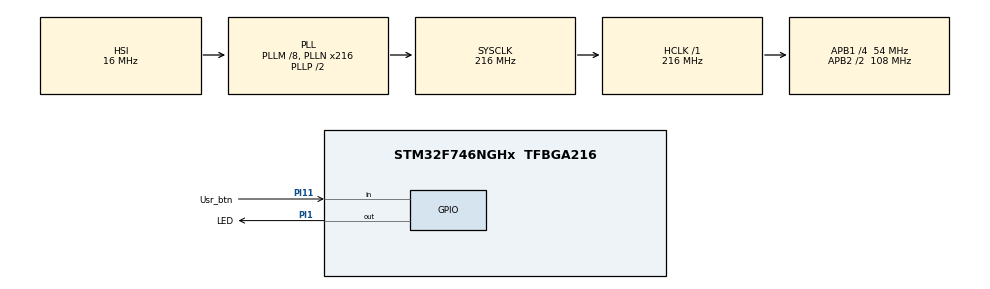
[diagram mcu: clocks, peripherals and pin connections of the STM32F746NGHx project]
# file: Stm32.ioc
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FREERTOS.Tasks01=defaultTask,24,128,StartDefaultTask,Default,NULL,Dynamic,NULL,NULL;ButtonTask,8,128,ButtonTask1,Default,NULL,Dynamic,NULL,NULL
Mcu.Family=STM32F7
Mcu.Name=STM32F746NGHx
Mcu.Package=TFBGA216
NVIC.PriorityGroup=NVIC_PRIORITYGROUP_4
PA13.Mode=Serial_Wire
PA13.Signal=SYS_JTMS-SWDIO
PA14.Mode=Serial_Wire
PA14.Signal=SYS_JTCK-SWCLK
PI1.GPIO_Label=LED
PI1.PinState=GPIO_PIN_SET
PI1.Signal=GPIO_Output
PI11.GPIO_Label=Usr_btn
PI11.Signal=GPIO_Input
ProjectManager.HeapSize=0x200
ProjectManager.StackSize=0x400
ProjectManager.TargetToolchain=STM32CubeIDE
RCC.AHBFreq_Value=216000000
RCC.APB1CLKDivider=RCC_HCLK_DIV4
RCC.APB1Freq_Value=54000000
RCC.APB1TimFreq_Value=108000000
RCC.APB2CLKDivider=RCC_HCLK_DIV2
RCC.APB2Freq_Value=108000000
RCC.APB2TimFreq_Value=216000000
RCC.CortexFreq_Value=216000000
RCC.HCLKFreq_Value=216000000
RCC.HSE_VALUE=25000000
RCC.HSI_VALUE=16000000
RCC.LSE_VALUE=32768
RCC.PLLM=8
RCC.PLLN=216
RCC.SYSCLKFreq_VALUE=216000000
RCC.SYSCLKSource=RCC_SYSCLKSOURCE_PLLCLK
RCC.USBFreq_Value=216000000
RCC.VCOOutputFreq_Value=432000000
VP_FREERTOS_VS_CMSIS_V2.Mode=CMSIS_V2
board=custom

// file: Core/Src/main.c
/* USER CODE BEGIN Header */
/**
  ******************************************************************************
  * @file           : main.c
  * @brief          : Main program body
  ******************************************************************************
  * @attention
  *
  * Copyright (c) 2024 STMicroelectronics.
  * All rights reserved.
  *
  * This software is licensed under terms that can be found in the LICENSE file
  * in the root directory of this software component.
  * If no LICENSE file comes with this software, it is provided AS-IS.
  *
  ******************************************************************************
  */
/* USER CODE END Header */
#include "main.h"
#include "cmsis_os.h"
#include "FreeRTOS.h"
#include "task.h"

/* Definitions for defaultTask */
osThreadId_t defaultTaskHandle;
const osThreadAttr_t defaultTask_attributes = {
  .name = "defaultTask",
  .stack_size = 128 * 4,
  .priority = (osPriority_t) osPriorityNormal,
};
/* Definitions for ButtonTask */
osThreadId_t ButtonTaskHandle;
const osThreadAttr_t ButtonTask_attributes = {
  .name = "ButtonTask",
  .stack_size = 128 * 4,
  .priority = (osPriority_t) osPriorityLow,
};

void SystemClock_Config(void);
static void MX_GPIO_Init(void);
void StartDefaultTask(void *argument);
void ButtonTask1(void *argument);

/* USER CODE BEGIN 0 */
uint8_t led_state = 1;
void BtnTsk1(void *argument)
	{
		GPIO_PinState button_state = GPIO_PIN_SET;
		GPIO_PinState last_button_state = GPIO_PIN_SET;
	  for(;;)
	  {
		  button_state=HAL_GPIO_ReadPin(Usr_btn_GPIO_Port, Usr_btn_Pin);
		  		  if (button_state != last_button_state)
		  		  {
		  			 if (button_state == GPIO_PIN_RESET)
		  			 {
		  				 led_state = !led_state;
		  				 HAL_GPIO_WritePin(LED_GPIO_Port, LED_Pin,led_state);
		  			 }
		  			 last_button_state = button_state;
		  		  }
	  }
	}
/* USER CODE END 0 */

int main(void)
{

  /* MCU Configuration--------------------------------------------------------*/

  /* Reset of all peripherals, Initializes the Flash interface and the Systick. */
  HAL_Init();

  /* Configure the system clock */
  SystemClock_Config();

  /* Initialize all configured peripherals */
  MX_GPIO_Init();

  /* Init scheduler */
  osKernelInitialize();

  /* Create the thread(s) */
  /* creation of defaultTask */
  defaultTaskHandle = osThreadNew(StartDefaultTask, NULL, &defaultTask_attributes);

  /* creation of ButtonTask */
  ButtonTaskHandle = osThreadNew(ButtonTask1, NULL, &ButtonTask_attributes);

  /* USER CODE BEGIN RTOS_EVENTS */
  	xTaskCreate(
  			  BtnTsk1,
			  "BTN_TSK",
			  50*4,
			  NULL,
			  tskIDLE_PRIORITY,
			  NULL);
  vTaskStartScheduler();
  /* USER CODE END RTOS_EVENTS */

  /* Start scheduler */
  osKernelStart();

  /* We should never get here as control is now taken by the scheduler */
  /* Infinite loop */
  /* USER CODE BEGIN WHILE */
  while (1)
  {
	  /*HAL_GPIO_WritePin(LED_GPIO_Port, LED_Pin,GPIO_PIN_RESET);
	  HAL_Delay(100);
	  HAL_GPIO_WritePin(LED_GPIO_Port, LED_Pin,GPIO_PIN_SET);
	  HAL_Delay(100);*/

    /* USER CODE END WHILE */

  }
}

void SystemClock_Config(void)
{
  RCC_OscInitTypeDef RCC_OscInitStruct = {0};
  RCC_ClkInitTypeDef RCC_ClkInitStruct = {0};

  /** Configure the main internal regulator output voltage
  */
  __HAL_RCC_PWR_CLK_ENABLE();
  __HAL_PWR_VOLTAGESCALING_CONFIG(PWR_REGULATOR_VOLTAGE_SCALE1);

  /** Initializes the RCC Oscillators according to the specified parameters
  * in the RCC_OscInitTypeDef structure.
  */
  RCC_OscInitStruct.OscillatorType = RCC_OSCILLATORTYPE_HSI;
  RCC_OscInitStruct.HSIState = RCC_HSI_ON;
  RCC_OscInitStruct.HSICalibrationValue = RCC_HSICALIBRATION_DEFAULT;
  RCC_OscInitStruct.PLL.PLLState = RCC_PLL_ON;
  RCC_OscInitStruct.PLL.PLLSource = RCC_PLLSOURCE_HSI;
  RCC_OscInitStruct.PLL.PLLM = 8;
  RCC_OscInitStruct.PLL.PLLN = 216;
  RCC_OscInitStruct.PLL.PLLP = RCC_PLLP_DIV2;
  RCC_OscInitStruct.PLL.PLLQ = 2;
  if (HAL_RCC_OscConfig(&RCC_OscInitStruct) != HAL_OK)
  {
    Error_Handler();
  }

  /** Activate the Over-Drive mode
  */
  if (HAL_PWREx_EnableOverDrive() != HAL_OK)
  {
    Error_Handler();
  }

  /** Initializes the CPU, AHB and APB buses clocks
  */
  RCC_ClkInitStruct.ClockType = RCC_CLOCKTYPE_HCLK|RCC_CLOCKTYPE_SYSCLK
                              |RCC_CLOCKTYPE_PCLK1|RCC_CLOCKTYPE_PCLK2;
  RCC_ClkInitStruct.SYSCLKSource = RCC_SYSCLKSOURCE_PLLCLK;
  RCC_ClkInitStruct.AHBCLKDivider = RCC_SYSCLK_DIV1;
  RCC_ClkInitStruct.APB1CLKDivider = RCC_HCLK_DIV4;
  RCC_ClkInitStruct.APB2CLKDivider = RCC_HCLK_DIV2;

  if (HAL_RCC_ClockConfig(&RCC_ClkInitStruct, FLASH_LATENCY_7) != HAL_OK)
  {
    Error_Handler();
  }
}

static void MX_GPIO_Init(void)
{
  GPIO_InitTypeDef GPIO_InitStruct = {0};

  /* GPIO Ports Clock Enable */
  __HAL_RCC_GPIOA_CLK_ENABLE();
  __HAL_RCC_GPIOI_CLK_ENABLE();

  /*Configure GPIO pin Output Level */
  HAL_GPIO_WritePin(LED_GPIO_Port, LED_Pin, GPIO_PIN_SET);

  /*Configure GPIO pin : LED_Pin */
  GPIO_InitStruct.Pin = LED_Pin;
  GPIO_InitStruct.Mode = GPIO_MODE_OUTPUT_PP;
  GPIO_InitStruct.Pull = GPIO_NOPULL;
  GPIO_InitStruct.Speed = GPIO_SPEED_FREQ_LOW;
  HAL_GPIO_Init(LED_GPIO_Port, &GPIO_InitStruct);

  /*Configure GPIO pin : Usr_btn_Pin */
  GPIO_InitStruct.Pin = Usr_btn_Pin;
  GPIO_InitStruct.Mode = GPIO_MODE_INPUT;
  GPIO_InitStruct.Pull = GPIO_NOPULL;
  HAL_GPIO_Init(Usr_btn_GPIO_Port, &GPIO_InitStruct);

}

void StartDefaultTask(void *argument)
{
  for(;;)
  {
    osDelay(1);
  }
}

void ButtonTask1(void *argument)
{
  /* USER CODE BEGIN ButtonTask1 */
	GPIO_PinState button_state = GPIO_PIN_SET;
	GPIO_PinState last_button_state = GPIO_PIN_SET;
  /* Infinite loop */
  for(;;)
  {
	  button_state=HAL_GPIO_ReadPin(Usr_btn_GPIO_Port, Usr_btn_Pin);
	  		  if (button_state != last_button_state)
	  		  {
	  			 if (button_state == GPIO_PIN_RESET)
	  			 {
	  				 led_state = !led_state;
	  				 HAL_GPIO_WritePin(LED_GPIO_Port, LED_Pin,led_state);
	  			 }
	  			 last_button_state = button_state;
	  		  }
  }
  /* USER CODE END ButtonTask1 */
}

void Error_Handler(void)
{
  __disable_irq();
  while (1)
  {
  }
}
